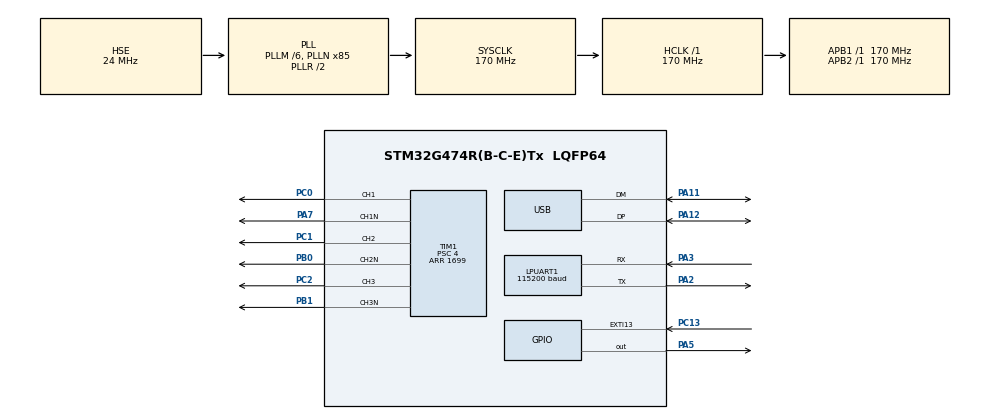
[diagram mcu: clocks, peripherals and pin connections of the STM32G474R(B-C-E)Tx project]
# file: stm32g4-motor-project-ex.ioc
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Dma.LPUART1_RX.0.Direction=DMA_PERIPH_TO_MEMORY
Dma.LPUART1_RX.0.EventEnable=DISABLE
Dma.LPUART1_RX.0.Instance=DMA1_Channel1
Dma.LPUART1_RX.0.MemDataAlignment=DMA_MDATAALIGN_BYTE
Dma.LPUART1_RX.0.MemInc=DMA_MINC_ENABLE
Dma.LPUART1_RX.0.Mode=DMA_NORMAL
Dma.LPUART1_RX.0.PeriphDataAlignment=DMA_PDATAALIGN_BYTE
Dma.LPUART1_RX.0.PeriphInc=DMA_PINC_DISABLE
Dma.LPUART1_RX.0.Polarity=HAL_DMAMUX_REQ_GEN_RISING
Dma.LPUART1_RX.0.Priority=DMA_PRIORITY_LOW
Dma.LPUART1_RX.0.RequestNumber=1
Dma.LPUART1_RX.0.SignalID=NONE
Dma.LPUART1_RX.0.SyncEnable=DISABLE
Dma.LPUART1_RX.0.SyncPolarity=HAL_DMAMUX_SYNC_NO_EVENT
Dma.LPUART1_RX.0.SyncRequestNumber=1
Dma.LPUART1_RX.0.SyncSignalID=NONE
Dma.LPUART1_TX.1.Direction=DMA_MEMORY_TO_PERIPH
Dma.LPUART1_TX.1.EventEnable=DISABLE
Dma.LPUART1_TX.1.Instance=DMA1_Channel2
Dma.LPUART1_TX.1.MemDataAlignment=DMA_MDATAALIGN_BYTE
Dma.LPUART1_TX.1.MemInc=DMA_MINC_ENABLE
Dma.LPUART1_TX.1.Mode=DMA_NORMAL
Dma.LPUART1_TX.1.PeriphDataAlignment=DMA_PDATAALIGN_BYTE
Dma.LPUART1_TX.1.PeriphInc=DMA_PINC_DISABLE
Dma.LPUART1_TX.1.Polarity=HAL_DMAMUX_REQ_GEN_RISING
Dma.LPUART1_TX.1.Priority=DMA_PRIORITY_LOW
Dma.LPUART1_TX.1.RequestNumber=1
Dma.LPUART1_TX.1.SignalID=NONE
Dma.LPUART1_TX.1.SyncEnable=DISABLE
Dma.LPUART1_TX.1.SyncPolarity=HAL_DMAMUX_SYNC_NO_EVENT
Dma.LPUART1_TX.1.SyncRequestNumber=1
Dma.LPUART1_TX.1.SyncSignalID=NONE
Dma.Request0=LPUART1_RX
Dma.Request1=LPUART1_TX
LPUART1.BaudRate=115200
Mcu.Family=STM32G4
Mcu.Name=STM32G474R(B-C-E)Tx
Mcu.Package=LQFP64
NVIC.DMA1_Channel1_IRQn=true\:0\:0\:false\:false\:true\:false\:false\:true\:true
NVIC.DMA1_Channel2_IRQn=true\:0\:0\:false\:false\:true\:false\:false\:true\:true
NVIC.LPUART1_IRQn=true\:0\:0\:false\:false\:true\:false\:false\:true\:true
NVIC.PriorityGroup=NVIC_PRIORITYGROUP_4
NVIC.TIM2_IRQn=true\:10\:0\:true\:false\:true\:false\:true\:true\:true
NVIC.TIM6_DAC_IRQn=true\:15\:0\:false\:false\:true\:false\:false\:true\:true
NVIC.TimeBase=TIM6_DAC_IRQn
NVIC.TimeBaseIP=TIM6
PA11.Mode=Device
PA11.Signal=USB_DM
PA12.Mode=Device
PA12.Signal=USB_DP
PA13.Mode=Serial_Wire
PA13.Signal=SYS_JTMS-SWDIO
PA14.Mode=Serial_Wire
PA14.Signal=SYS_JTCK-SWCLK
PA2.Mode=Asynchronous
PA2.Signal=LPUART1_TX
PA3.Mode=Asynchronous
PA3.Signal=LPUART1_RX
PA5.Signal=GPIO_Output
PA7.Mode=PWM Generation1 CH1 CH1N
PA7.Signal=TIM1_CH1N
PB0.Mode=PWM Generation2 CH2 CH2N
PB0.Signal=TIM1_CH2N
PB1.Mode=PWM Generation3 CH3 CH3N
PB1.Signal=TIM1_CH3N
PC0.Signal=S_TIM1_CH1
PC1.Signal=S_TIM1_CH2
PC13.Signal=GPXTI13
PC14-OSC32_IN.Mode=LSE-External-Oscillator
PC14-OSC32_IN.Signal=RCC_OSC32_IN
PC15-OSC32_OUT.Mode=LSE-External-Oscillator
PC15-OSC32_OUT.Signal=RCC_OSC32_OUT
PC2.Signal=S_TIM1_CH3
PF0-OSC_IN.Mode=HSE-External-Oscillator
PF0-OSC_IN.Signal=RCC_OSC_IN
PF1-OSC_OUT.Mode=HSE-External-Oscillator
PF1-OSC_OUT.Signal=RCC_OSC_OUT
ProjectManager.HeapSize=0x200
ProjectManager.StackSize=0x400
ProjectManager.TargetToolchain=CMake
RCC.ADC12Freq_Value=170000000
RCC.ADC345Freq_Value=170000000
RCC.AHBFreq_Value=170000000
RCC.APB1Freq_Value=170000000
RCC.APB1TimFreq_Value=170000000
RCC.APB2Freq_Value=170000000
RCC.APB2TimFreq_Value=170000000
RCC.CK48CLockSelection=RCC_USBCLKSOURCE_HSI48
RCC.CortexFreq_Value=170000000
RCC.EXTERNAL_CLOCK_VALUE=12288000
RCC.HCLKFreq_Value=170000000
RCC.HSE_VALUE=24000000
RCC.HSI48_VALUE=48000000
RCC.HSI_VALUE=16000000
RCC.PLLM=RCC_PLLM_DIV6
RCC.PLLN=85
RCC.PLLSourceVirtual=RCC_PLLSOURCE_HSE
RCC.SYSCLKFreq_VALUE=170000000
RCC.SYSCLKSource=RCC_SYSCLKSOURCE_PLLCLK
RCC.USBFreq_Value=48000000
RCC.VCOOutputFreq_Value=340000000
SH.S_TIM1_CH1.0=TIM1_CH1,PWM Generation1 CH1 CH1N
SH.S_TIM1_CH2.0=TIM1_CH2,PWM Generation2 CH2 CH2N
SH.S_TIM1_CH3.0=TIM1_CH3,PWM Generation3 CH3 CH3N
STMicroelectronics.X-CUBE-AZRTOS-G4.2.0.0.FX_APP_MEM_POOL_SIZE=2048
STMicroelectronics.X-CUBE-AZRTOS-G4.2.0.0.FileXCcFileOoSystemJjFileXJjCore=true
STMicroelectronics.X-CUBE-AZRTOS-G4.2.0.0.TX_APP_CREATION=1
STMicroelectronics.X-CUBE-AZRTOS-G4.2.0.0.TX_APP_GENERATE_INIT_CODE=true
STMicroelectronics.X-CUBE-AZRTOS-G4.2.0.0.TX_APP_MEM_POOL_SIZE=8192
STMicroelectronics.X-CUBE-AZRTOS-G4.2.0.0.TX_APP_MUTEX_CREATION=1
STMicroelectronics.X-CUBE-AZRTOS-G4.2.0.0.ThreadXCcRTOSJjThreadXJjCore=true
STMicroelectronics.X-CUBE-AZRTOS-G4.2.0.0.ThreadXCcRTOSJjThreadXJjLowOoPowerOosupport=true
STMicroelectronics.X-CUBE-AZRTOS-G4.2.0.0.ThreadXCcRTOSJjThreadXJjPerformanceInfo=true
STMicroelectronics.X-CUBE-AZRTOS-G4.2.0.0.ThreadXCcRTOSJjThreadXJjTraceXOosupport=true
STMicroelectronics.X-CUBE-AZRTOS-G4.2.0.0.USBXCcUSBJjUSBXJjCoreSystem=true
STMicroelectronics.X-CUBE-AZRTOS-G4.2.0.0_IsAnAzureRtosMw=true
TIM1.AsymmetricalDeadTime=ENABLE
TIM1.AutoReloadPreload=TIM_AUTORELOAD_PRELOAD_ENABLE
TIM1.AutomaticOutput=TIM_AUTOMATICOUTPUT_DISABLE
TIM1.BreakState=TIM_BREAK_ENABLE
TIM1.Channel-PWM\ Generation1\ CH1\ CH1N=TIM_CHANNEL_1
TIM1.Channel-PWM\ Generation2\ CH2\ CH2N=TIM_CHANNEL_2
TIM1.Channel-PWM\ Generation3\ CH3\ CH3N=TIM_CHANNEL_3
TIM1.CounterMode=TIM_COUNTERMODE_CENTERALIGNED1
TIM1.DeadTime=34
TIM1.DeadTimePreload=ENABLE
TIM1.PeriodNoDither=1699
TIM1.Prescaler=4
TIM2.AutoReloadPreload=TIM_AUTORELOAD_PRELOAD_ENABLE
TIM2.PeriodNoDither=10000
TIM2.Prescaler=1700-1
VP_CORDIC_VS_CORDIC.Mode=CORDIC_Activate
VP_STMicroelectronics.X-CUBE-AZRTOS-G4_VS_FileOoSystemJjFileX_6.2.0_2.0.0.Mode=FileOoSystemJjFileX
VP_STMicroelectronics.X-CUBE-AZRTOS-G4_VS_RTOSJjThreadX_6.2.0_2.0.0.Mode=RTOSJjThreadX
VP_STMicroelectronics.X-CUBE-AZRTOS-G4_VS_USBJjUSBX_6.2.0_2.0.0.Mode=USBJjUSBX
VP_SYS_VS_DBSignals.Mode=DisableDeadBatterySignals
VP_SYS_VS_tim6.Mode=TIM6
VP_TIM1_VS_ClockSourceINT.Mode=Internal
VP_TIM2_VS_ClockSourceINT.Mode=Internal
board=custom

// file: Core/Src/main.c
/* USER CODE BEGIN Header */
/**
  ******************************************************************************
  * @file           : main.c
  * @brief          : Main program body
  ******************************************************************************
  * @attention
  *
  * Copyright (c) 2025 STMicroelectronics.
  * All rights reserved.
  *
  * This software is licensed under terms that can be found in the LICENSE file
  * in the root directory of this software component.
  * If no LICENSE file comes with this software, it is provided AS-IS.
  *
  ******************************************************************************
  */
/* USER CODE END Header */
#include "app_threadx.h"
#include "main.h"
#include "cordic.h"
#include "dma.h"
#include "usart.h"
#include "tim.h"
#include "usb.h"
#include "gpio.h"

/* USER CODE BEGIN Includes */
#include "vofa_com_threadx.h"
/* USER CODE END Includes */

void SystemClock_Config(void);
/* USER CODE BEGIN PFP */
static void CCMRAM_Example(void);

/* USER CODE END PFP */

int main(void)
{

  /* MCU Configuration--------------------------------------------------------*/

  /* Reset of all peripherals, Initializes the Flash interface and the Systick. */
  HAL_Init();

  /* Configure the system clock */
  SystemClock_Config();

  /* Initialize all configured peripherals */
  MX_GPIO_Init();
  MX_DMA_Init();
  MX_LPUART1_UART_Init();
  MX_CORDIC_Init();
  MX_TIM2_Init();
  MX_USB_PCD_Init();
  MX_TIM1_Init();

  MX_ThreadX_Init();

  /* We should never get here as control is now taken by the scheduler */

  /* Infinite loop */
  while (1)
  {

  }
}

void SystemClock_Config(void)
{
  RCC_OscInitTypeDef RCC_OscInitStruct = {0};
  RCC_ClkInitTypeDef RCC_ClkInitStruct = {0};

  /** Configure the main internal regulator output voltage
  */
  HAL_PWREx_ControlVoltageScaling(PWR_REGULATOR_VOLTAGE_SCALE1_BOOST);

  /** Initializes the RCC Oscillators according to the specified parameters
  * in the RCC_OscInitTypeDef structure.
  */
  RCC_OscInitStruct.OscillatorType = RCC_OSCILLATORTYPE_HSI48|RCC_OSCILLATORTYPE_HSE;
  RCC_OscInitStruct.HSEState = RCC_HSE_ON;
  RCC_OscInitStruct.HSI48State = RCC_HSI48_ON;
  RCC_OscInitStruct.PLL.PLLState = RCC_PLL_ON;
  RCC_OscInitStruct.PLL.PLLSource = RCC_PLLSOURCE_HSE;
  RCC_OscInitStruct.PLL.PLLM = RCC_PLLM_DIV6;
  RCC_OscInitStruct.PLL.PLLN = 85;
  RCC_OscInitStruct.PLL.PLLP = RCC_PLLP_DIV2;
  RCC_OscInitStruct.PLL.PLLQ = RCC_PLLQ_DIV2;
  RCC_OscInitStruct.PLL.PLLR = RCC_PLLR_DIV2;
  if (HAL_RCC_OscConfig(&RCC_OscInitStruct) != HAL_OK)
  {
    Error_Handler();
  }

  /** Initializes the CPU, AHB and APB buses clocks
  */
  RCC_ClkInitStruct.ClockType = RCC_CLOCKTYPE_HCLK|RCC_CLOCKTYPE_SYSCLK
                              |RCC_CLOCKTYPE_PCLK1|RCC_CLOCKTYPE_PCLK2;
  RCC_ClkInitStruct.SYSCLKSource = RCC_SYSCLKSOURCE_PLLCLK;
  RCC_ClkInitStruct.AHBCLKDivider = RCC_SYSCLK_DIV1;
  RCC_ClkInitStruct.APB1CLKDivider = RCC_HCLK_DIV1;
  RCC_ClkInitStruct.APB2CLKDivider = RCC_HCLK_DIV1;

  if (HAL_RCC_ClockConfig(&RCC_ClkInitStruct, FLASH_LATENCY_4) != HAL_OK)
  {
    Error_Handler();
  }
}

void HAL_TIM_PeriodElapsedCallback(TIM_HandleTypeDef *htim)
{
  if (htim->Instance == TIM6) {
    HAL_IncTick();
  }
  /* USER CODE BEGIN Callback 1 */

  /* 查询是否为TIM2中断，释放信号量通知线程发�?�数�? */
  if (htim->Instance == TIM2) {
    tx_semaphore_put(&vofa_timer_semaphore);
  }

  /* USER CODE END Callback 1 */
}

void Error_Handler(void)
{
  __disable_irq();
  while (1)
  {
  }
}
